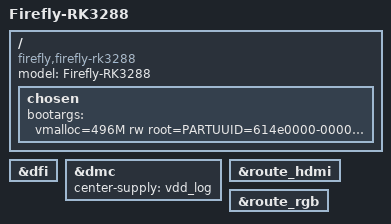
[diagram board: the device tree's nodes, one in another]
// SPDX-License-Identifier: (GPL-2.0+ OR MIT)
/*
 * Copyright (c) 2014, 2015 FUKAUMI Naoki <naobsd@gmail.com>
 */

/dts-v1/;
#include "rk3288-ff-20160623.dtsi"
#include "rk3288-linux.dtsi"

/ {
	model = "Firefly-RK3288";
	compatible = "firefly,firefly-rk3288", "rockchip,rk3288";

	chosen {
		bootargs = "vmalloc=496M rw root=PARTUUID=614e0000-0000 rootfstype=ext4 rootwait";
	};
};

&dfi {
	status = "okay";
};

&dmc {
	center-supply = <&vdd_log>;
	status = "okay";
};

&route_hdmi {
	status = "okay";
};

&route_rgb {
	status = "okay";
};
